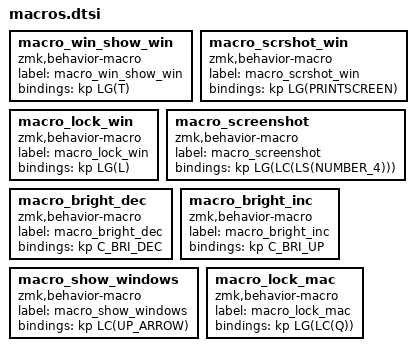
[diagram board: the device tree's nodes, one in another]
macro_win_show_win: macro_win_show_win{
compatible = "zmk,behavior-macro";
label = "macro_win_show_win";
#binding-cells = <0>;
bindings = <&kp LG(T)>;
};
macro_scrshot_win: macro_scrshot_win{
compatible = "zmk,behavior-macro";
label = "macro_scrshot_win";
#binding-cells = <0>;
bindings = <&kp LG(PRINTSCREEN)>;
};
macro_lock_win: macro_lock_win{
compatible = "zmk,behavior-macro";
label = "macro_lock_win";
#binding-cells = <0>;
bindings = <&kp LG(L)>;
};
macro_screenshot: macro_screenshot{
compatible = "zmk,behavior-macro";
label = "macro_screenshot";
#binding-cells = <0>;
bindings = <&kp LG(LC(LS(NUMBER_4)))>;
};
macro_bright_dec: macro_bright_dec{
compatible = "zmk,behavior-macro";
label = "macro_bright_dec";
#binding-cells = <0>;
bindings = <&kp C_BRI_DEC>;
};
macro_bright_inc: macro_bright_inc{
compatible = "zmk,behavior-macro";
label = "macro_bright_inc";
#binding-cells = <0>;
bindings = <&kp C_BRI_UP>;
};
macro_show_windows: macro_show_windows{
compatible = "zmk,behavior-macro";
label = "macro_show_windows";
#binding-cells = <0>;
bindings = <&kp LC(UP_ARROW)>;
};
macro_lock_mac: macro_lock_mac{
compatible = "zmk,behavior-macro";
label = "macro_lock_mac";
#binding-cells = <0>;
bindings = <&kp LG(LC(Q))>;
};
